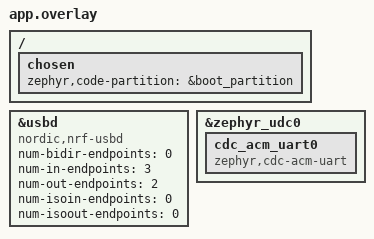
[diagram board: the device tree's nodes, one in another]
/*
 * Copyright (c) 2024 Nordic Semiconductor ASA
 *
 * SPDX-License-Identifier: LicenseRef-Nordic-5-Clause
 */

/ {
	chosen {
		zephyr,code-partition = &boot_partition;
	};
};

/* The USB is used only for MCUboot serial recovery over CDC ACM class.
 * Reduce number of endpoints to save memory.
 */
&usbd {
	compatible = "nordic,nrf-usbd";
	status = "okay";
	num-bidir-endpoints = <0>;
	num-in-endpoints = <3>;
	num-out-endpoints = <2>;
	num-isoin-endpoints = <0>;
	num-isoout-endpoints = <0>;
};

&zephyr_udc0 {
	cdc_acm_uart0: cdc_acm_uart0 {
		compatible = "zephyr,cdc-acm-uart";
	};
};
